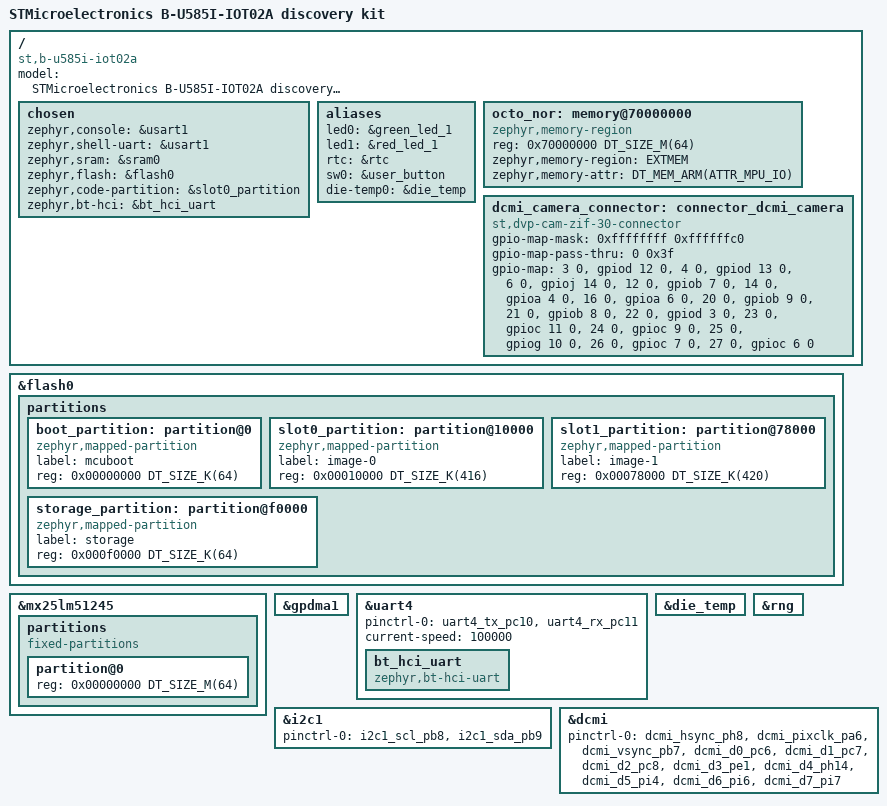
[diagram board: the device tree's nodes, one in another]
/*
 * Copyright (c) 2021 STMicroelectronics
 *
 * SPDX-License-Identifier: Apache-2.0
 */

/dts-v1/;
#include "b_u585i_iot02a-common.dtsi"
#include <zephyr/dt-bindings/memory-attr/memory-attr.h>
#include <zephyr/dt-bindings/memory-attr/memory-attr-arm.h>

/ {
	model = "STMicroelectronics B-U585I-IOT02A discovery kit";
	compatible = "st,b-u585i-iot02a";

	chosen {
		zephyr,console = &usart1;
		zephyr,shell-uart = &usart1;
		zephyr,sram = &sram0;
		zephyr,flash = &flash0;
		zephyr,code-partition = &slot0_partition;
		zephyr,bt-hci = &bt_hci_uart;
	};

	aliases {
		led0 = &green_led_1;
		led1 = &red_led_1;
		rtc = &rtc;
		sw0 = &user_button;
		die-temp0 = &die_temp;
	};

	octo_nor: memory@70000000 {
		compatible = "zephyr,memory-region";
		reg = <0x70000000 DT_SIZE_M(64)>;
		zephyr,memory-region = "EXTMEM";
		/* The ATTR_MPU_EXTMEM attribute causing a MPU FAULT */
		zephyr,memory-attr = <DT_MEM_ARM(ATTR_MPU_IO)>;
	};

	/* TO BE FIXED */
	dcmi_camera_connector: connector_dcmi_camera {
		compatible = "st,dvp-cam-zif-30-connector";
		#gpio-cells = <2>;
		gpio-map-mask = <0xffffffff 0xffffffc0>;
		gpio-map-pass-thru = <0 0x3f>;
		gpio-map = <3 0 &gpiod 12 0>,  /* I2C4_SCL */
			   <4 0 &gpiod 13 0>,  /* I2C4_SDA */
			   /* RESET is directly connected to MCU reset */
			   <6 0 &gpioj 14 0>,  /* PWDN_EN */
			   <12 0 &gpiob 7 0>,  /* DCMI_VSYNC */
			   <14 0 &gpioa 4 0>,  /* DCMI_HSYNC */
			   <16 0 &gpioa 6 0>,  /* DCMI_PIXCK */
			   <20 0 &gpiob 9 0>,  /* DCMI_D7 */
			   <21 0 &gpiob 8 0>,  /* DCMI_D6 */
			   <22 0 &gpiod 3 0>,  /* DCMI_D5 */
			   <23 0 &gpioc 11 0>,  /* DCMI_D4 */
			   <24 0 &gpioc 9 0>,  /* DCMI_D3 */
			   <25 0 &gpiog 10 0>,  /* DCMI_D2 */
			   <26 0 &gpioc 7 0>,  /* DCMI_D1 */
			   <27 0 &gpioc 6 0>;  /* DCMI_D0 */
	};
	/* END OF TO BE FIXED */
};

&flash0 {
	partitions {
		#address-cells = <1>;
		#size-cells = <1>;
		ranges;

		/*
		 * Following flash partition is dedicated to the use of b_u585i_iot02a
		 * with TZEN=0 (so w/o TFM).
		 * Set the partitions with first MB to make use of the whole Bank1
		 */
		boot_partition: partition@0 {
			compatible = "zephyr,mapped-partition";
			label = "mcuboot";
			reg = <0x00000000 DT_SIZE_K(64)>;
		};

		slot0_partition: partition@10000 {
			compatible = "zephyr,mapped-partition";
			label = "image-0";
			reg = <0x00010000 DT_SIZE_K(416)>;
		};

		slot1_partition: partition@78000 {
			compatible = "zephyr,mapped-partition";
			label = "image-1";
			reg = <0x00078000 DT_SIZE_K(420)>;
		};

		/* Unused range [0xe1000..0xeffff] */

		storage_partition: partition@f0000 {
			compatible = "zephyr,mapped-partition";
			label = "storage";
			reg = <0x000f0000 DT_SIZE_K(64)>;
		};
	};
};

&mx25lm51245 {
	partitions {
		compatible = "fixed-partitions";
		#address-cells = <1>;
		#size-cells = <1>;

		partition@0 {
			reg = <0x00000000 DT_SIZE_M(64)>;
		};
	};
};

&gpdma1 {
	status = "okay";
};

&uart4 {
	pinctrl-0 = <&uart4_tx_pc10 &uart4_rx_pc11>;
	pinctrl-names = "default";
	current-speed = <100000>;
	status = "okay";

	bt_hci_uart: bt_hci_uart {
		compatible = "zephyr,bt-hci-uart";
		status = "okay";
	};
};

&die_temp {
	status = "okay";
};

&rng {
	status = "okay";
};

st_cam_i2c: &i2c1 {
	pinctrl-0 = <&i2c1_scl_pb8 &i2c1_sda_pb9>;
	pinctrl-names = "default";
}

st_cam_dvp: &dcmi {
	pinctrl-0 = <&dcmi_hsync_ph8 &dcmi_pixclk_pa6 &dcmi_vsync_pb7
		     &dcmi_d0_pc6 &dcmi_d1_pc7 &dcmi_d2_pc8 &dcmi_d3_pe1
		     &dcmi_d4_ph14 &dcmi_d5_pi4 &dcmi_d6_pi6 &dcmi_d7_pi7>;
	pinctrl-names = "default";
};
